# MKL33Z4 register map
Vendor: Freescale Semiconductor, Inc.; File version: 1.6
MKL33Z4 Freescale Microcontroller
CPU: CM0PLUS r0p0, little endian, no MPU, no FPU, 0x2 interrupt priority bits, 0x0 interrupts
Registers are 32-bit, read-write, reset 0x0 unless marked. A register's access mark holds for its fields unless they carry their own. Offsets are from the block's base; lines under a group give offsets from that group; [hi:lo] are bit positions; {n}, {i} and the like mark numbered series; 'fields as' and 'values as' point back to an identical list; <NAME> marks a mode.

## Memory map
0x00000400 FTFA_FlashConfig size 0xE — Flash configuration field
0x40008000 DMA blocks up to offset 0x140 — DMA Controller
0x40020000 FTFA size 0x14 — Flash Memory Interface
0x40021000 DMAMUX0 size 0x4 — DMA channel multiplexor
0x4002F000 I2S0 size 0x104 — Inter-IC Sound / Synchronous Audio Interface
0x40037000 PIT size 0x120 — Periodic Interrupt Timer
0x40038000 TPM0 size 0x88 — Timer/PWM Module
0x40039000 TPM1 size 0x88 — Timer/PWM Module
0x4003A000 TPM2 size 0x88 — Timer/PWM Module
0x4003B000 ADC0 size 0x70 — Analog-to-Digital Converter
0x4003D000 RTC size 0x20 — Secure Real Time Clock
0x4003F000 DAC0 size 0x24 — 12-Bit Digital-to-Analog Converter
0x40040000 LPTMR0 size 0x10 — Low Power Timer
0x40041000 RFSYS size 0x20 — System register file
0x40047000 SIM size 0x1108 — System Integration Module
0x40049000 PORTA size 0xA4 — Pin Control and Interrupts
0x4004A000 PORTB size 0xA4 — Pin Control and Interrupts
0x4004B000 PORTC size 0xA4 — Pin Control and Interrupts
0x4004C000 PORTD size 0xA4 — Pin Control and Interrupts
0x4004D000 PORTE size 0xA4 — Pin Control and Interrupts
0x40053000 LCD size 0x60 — Segment Liquid Crystal Display
0x40054000 LPUART0 size 0x14 — Universal Asynchronous Receiver/Transmitter
0x40055000 LPUART1 size 0x14 — Universal Asynchronous Receiver/Transmitter
0x4005F000 FLEXIO size 0x510 — The FLEXIO Memory Map/Register Definition can be found here.
0x40064000 MCG size 0x1C — Multipurpose Clock Generator Lite
0x40065000 OSC0 size 0x1 — Oscillator
0x40066000 I2C0 size 0xD — Inter-Integrated Circuit
0x40067000 I2C1 size 0xD — Inter-Integrated Circuit
0x4006C000 UART2 size 0x40 — Serial Communication Interface
0x40073000 CMP0 size 0x6 — High-Speed Comparator (CMP), Voltage Reference (VREF) Digital-to-Analog Converter (DAC), and Analog Mux (ANMUX)
0x40074000 VREF size 0x2 — Voltage Reference
0x40076000 SPI0 size 0x8 — Serial Peripheral Interface
0x40077000 SPI1 size 0xC — Serial Peripheral Interface
0x4007C000 LLWU size 0xA — Low leakage wakeup unit
0x4007D000 PMC size 0x3 — Power Management Controller
0x4007E000 SMC size 0x4 — System Mode Controller
0x4007F000 RCM size 0xA — Reset Control Module
0x400FF000 GPIOA size 0x18 — General Purpose Input/Output
0x400FF040 GPIOB size 0x18 — General Purpose Input/Output
0x400FF080 GPIOC size 0x18 — General Purpose Input/Output
0x400FF0C0 GPIOD size 0x18 — General Purpose Input/Output
0x400FF100 GPIOE size 0x18 — General Purpose Input/Output
0xF0000000 MTB size 0x1000 — Micro Trace Buffer
0xF0001000 MTBDWT size 0x1000 — MTB data watchpoint and trace
0xF0002000 ROM size 0x1000 — System ROM
0xF0003000 MCM blocks up to offset 0x44 — Core Platform Miscellaneous Control Module
0xF8000000 FGPIOA size 0x18 — General Purpose Input/Output
0xF8000040 FGPIOB size 0x18 — General Purpose Input/Output
0xF8000080 FGPIOC size 0x18 — General Purpose Input/Output
0xF80000C0 FGPIOD size 0x18 — General Purpose Input/Output
0xF8000100 FGPIOE size 0x18 — General Purpose Input/Output

## Interrupts
0 DMA0 (DMA)
1 DMA1 (DMA)
2 DMA2 (DMA)
3 DMA3 (DMA)
5 FTFA
6 PMC
7 LLWU
8 I2C0
9 I2C1
10 SPI0
11 SPI1
12 LPUART0
13 LPUART1
14 UART2_FLEXIO (FLEXIO, UART2)
15 ADC0
16 CMP0
17 TPM0
18 TPM1
19 TPM2
20 RTC
21 RTC_Seconds (RTC)
22 PIT
23 I2S0
25 DAC0
28 LPTMR0
29 LCD
30 PORTA (PORTA, GPIOA)
31 PORTC_PORTD (PORTC, PORTD, GPIOC, GPIOD)

## FTFA_FlashConfig — Flash configuration field
Base 0x00000400; register names take the prefix NV_
0x00 BACKKEY3 8-bit ro reset 0xFF — Backdoor Comparison Key 3.
  [7:0] KEY — Backdoor Comparison Key.
0x01 BACKKEY2 8-bit ro reset 0xFF — Backdoor Comparison Key 2.
  [7:0] KEY — Backdoor Comparison Key.
0x02 BACKKEY1 8-bit ro reset 0xFF — Backdoor Comparison Key 1.
  [7:0] KEY — Backdoor Comparison Key.
0x03 BACKKEY0 8-bit ro reset 0xFF — Backdoor Comparison Key 0.
  [7:0] KEY — Backdoor Comparison Key.
0x04 BACKKEY7 8-bit ro reset 0xFF — Backdoor Comparison Key 7.
  [7:0] KEY — Backdoor Comparison Key.
0x05 BACKKEY6 8-bit ro reset 0xFF — Backdoor Comparison Key 6.
  [7:0] KEY — Backdoor Comparison Key.
0x06 BACKKEY5 8-bit ro reset 0xFF — Backdoor Comparison Key 5.
  [7:0] KEY — Backdoor Comparison Key.
0x07 BACKKEY4 8-bit ro reset 0xFF — Backdoor Comparison Key 4.
  [7:0] KEY — Backdoor Comparison Key.
0x08 FPROT3 8-bit ro reset 0xFF — Non-volatile P-Flash Protection 1 - Low Register
  [7:0] PROT — P-Flash Region Protect
0x09 FPROT2 8-bit ro reset 0xFF — Non-volatile P-Flash Protection 1 - High Register
  [7:0] PROT — P-Flash Region Protect
0x0A FPROT1 8-bit ro reset 0xFF — Non-volatile P-Flash Protection 0 - Low Register
  [7:0] PROT — P-Flash Region Protect
0x0B FPROT0 8-bit ro reset 0xFF — Non-volatile P-Flash Protection 0 - High Register
  [7:0] PROT — P-Flash Region Protect
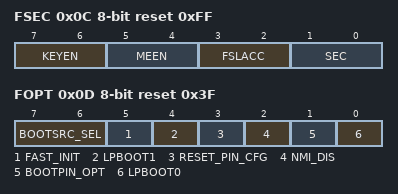
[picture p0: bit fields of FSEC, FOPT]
0x0C FSEC 8-bit ro reset 0xFF — Non-volatile Flash Security Register
  [7:6] KEYEN — Backdoor Key Security Enable
    2=Backdoor key access enabled; 3=Backdoor key access disabled
  [5:4] MEEN
    2=Mass erase is disabled; 3=Mass erase is enabled
  [3:2] FSLACC — Freescale Failure Analysis Access Code
    2=Freescale factory access denied; 3=Freescale factory access granted
  [1:0] SEC — Flash Security
    2=MCU security status is unsecure; 3=MCU security status is secure
0x0D FOPT 8-bit ro reset 0x3F — Non-volatile Flash Option Register
  [7:6] BOOTSRC_SEL — Boot source selection
    0=Boot from Flash; 2=Boot from ROM; 3=Boot from ROM
  [5] FAST_INIT
    0=Slower initialization; 1=Fast Initialization
  [4] LPBOOT1
    0=Core and system clock divider (OUTDIV1) is 0x7 (divide by 8) when LPBOOT0=0 or 0x3 (divide by 4) when LPBOOT0=1; 1=Core and system clock divider (OUTDIV1) is 0x1 (divide by 2) when LPBOOT0=0 or 0x0 (divide by 1) when LPBOOT0=1
  [3] RESET_PIN_CFG
    0=RESET pin is disabled following a POR and cannot be enabled as reset function; 1=RESET_b pin is dedicated
  [2] NMI_DIS
    0=NMI interrupts are always blocked; 1=NMI_b pin/interrupts reset default to enabled
  [1] BOOTPIN_OPT
    0=Force Boot from ROM if BOOTCFG0 asserted, where BOOTCFG0 is the boot config function which is muxed with NMI pin; 1=Boot source configured by FOPT (BOOTSRC_SEL) bits
  [0] LPBOOT0
    0=Core and system clock divider (OUTDIV1) is 0x7 (divide by 8) when LPBOOT1=0 or 0x1 (divide by 2) when LPBOOT1=1; 1=Core and system clock divider (OUTDIV1) is 0x3 (divide by 4) when LPBOOT1=0 or 0x0 (divide by 1) when LPBOOT1=1
